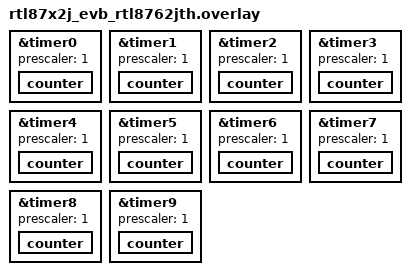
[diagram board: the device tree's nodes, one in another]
/*
 * Copyright (c) 2026, Realtek Semiconductor Corporation
 *
 * SPDX-License-Identifier: Apache-2.0
 */

&timer0 {
	prescaler = <1>;
	status = "okay";

	counter {
		status = "okay";
	};
};

&timer1 {
	prescaler = <1>;
	status = "okay";

	counter {
		status = "okay";
	};
};

&timer2 {
	prescaler = <1>;
	status = "okay";

	counter {
		status = "okay";
	};
};

&timer3 {
	prescaler = <1>;
	status = "okay";

	counter {
		status = "okay";
	};
};

&timer4 {
	prescaler = <1>;
	status = "okay";

	counter {
		status = "okay";
	};
};

&timer5 {
	prescaler = <1>;
	status = "okay";

	counter {
		status = "okay";
	};
};

&timer6 {
	prescaler = <1>;
	status = "okay";

	counter {
		status = "okay";
	};
};

&timer7 {
	prescaler = <1>;
	status = "okay";

	counter {
		status = "okay";
	};
};

&timer8 {
	prescaler = <1>;
	status = "okay";

	counter {
		status = "okay";
	};
};

&timer9 {
	prescaler = <1>;
	status = "okay";

	counter {
		status = "okay";
	};
};
